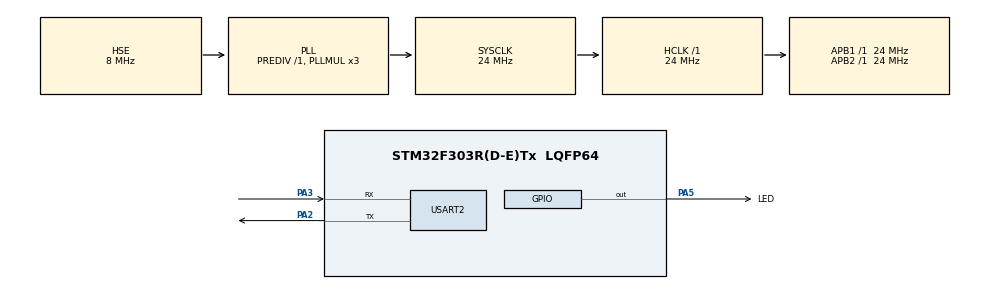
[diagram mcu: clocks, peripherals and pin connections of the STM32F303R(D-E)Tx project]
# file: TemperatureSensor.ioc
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ADC1.Channel-0\#ChannelRegularConversion=ADC_CHANNEL_VREFINT
ADC1.Channel-1\#ChannelRegularConversion=ADC_CHANNEL_TEMPSENSOR
ADC1.ClockPrescaler=ADC_CLOCK_SYNC_PCLK_DIV4
ADC1.DMAContinuousRequests=ENABLE
ADC1.DiscontinuousConvMode=DISABLE
ADC1.EOCSelection=ADC_EOC_SINGLE_CONV
ADC1.ExternalTrigConv=ADC_EXTERNALTRIGCONV_T3_TRGO
ADC1.ExternalTrigConvEdge=ADC_EXTERNALTRIGCONVEDGE_FALLING
ADC1.NbrOfConversion=2
ADC1.NbrOfConversionFlag=1
ADC1.Offset-0\#ChannelRegularConversion=0
ADC1.Offset-1\#ChannelRegularConversion=0
ADC1.OffsetNumber-0\#ChannelRegularConversion=ADC_OFFSET_NONE
ADC1.OffsetNumber-1\#ChannelRegularConversion=ADC_OFFSET_NONE
ADC1.Rank-0\#ChannelRegularConversion=1
ADC1.Rank-1\#ChannelRegularConversion=2
ADC1.SamplingTime-0\#ChannelRegularConversion=ADC_SAMPLETIME_601CYCLES_5
ADC1.SamplingTime-1\#ChannelRegularConversion=ADC_SAMPLETIME_601CYCLES_5
ADC1.SamplingTimeOPAMP-1\#ChannelRegularConversion=ADC_SAMPLETIME_7CYCLES_5
ADC1.master=1
Dma.ADC1.0.Direction=DMA_PERIPH_TO_MEMORY
Dma.ADC1.0.Instance=DMA1_Channel1
Dma.ADC1.0.MemDataAlignment=DMA_MDATAALIGN_HALFWORD
Dma.ADC1.0.MemInc=DMA_MINC_ENABLE
Dma.ADC1.0.Mode=DMA_CIRCULAR
Dma.ADC1.0.PeriphDataAlignment=DMA_PDATAALIGN_HALFWORD
Dma.ADC1.0.PeriphInc=DMA_PINC_DISABLE
Dma.ADC1.0.Priority=DMA_PRIORITY_LOW
Dma.Request0=ADC1
Mcu.Family=STM32F3
Mcu.Name=STM32F303R(D-E)Tx
Mcu.Package=LQFP64
NVIC.ADC1_2_IRQn=true\:0\:0\:false\:false\:true\:true\:true\:true
NVIC.DMA1_Channel1_IRQn=true\:0\:0\:false\:false\:true\:false\:true\:true
NVIC.PriorityGroup=NVIC_PRIORITYGROUP_4
NVIC.TIM3_IRQn=true\:0\:0\:false\:false\:true\:true\:true\:true
PA13.Mode=Serial_Wire
PA13.Signal=SYS_JTMS-SWDIO
PA14.Mode=Serial_Wire
PA14.Signal=SYS_JTCK-SWCLK
PA2.Mode=Asynchronous
PA2.Signal=USART2_TX
PA3.Mode=Asynchronous
PA3.Signal=USART2_RX
PA5.GPIO_Label=LED
PA5.Signal=GPIO_Output
PC14-OSC32_IN.Mode=LSE-External-Oscillator
PC14-OSC32_IN.Signal=RCC_OSC32_IN
PC15-OSC32_OUT.Mode=LSE-External-Oscillator
PC15-OSC32_OUT.Signal=RCC_OSC32_OUT
PF0-OSC_IN.Mode=HSE-External-Clock-Source
PF0-OSC_IN.Signal=RCC_OSC_IN
ProjectManager.HeapSize=0x200
ProjectManager.StackSize=0x400
ProjectManager.TargetToolchain=STM32CubeIDE
RCC.AHBFreq_Value=24000000
RCC.APB1Freq_Value=24000000
RCC.APB1TimFreq_Value=24000000
RCC.APB2Freq_Value=24000000
RCC.APB2TimFreq_Value=24000000
RCC.CortexFreq_Value=24000000
RCC.HCLKFreq_Value=24000000
RCC.HSE_VALUE=8000000
RCC.HSI_VALUE=8000000
RCC.PLLMUL=RCC_PLL_MUL3
RCC.PLLSourceVirtual=RCC_PLLSOURCE_HSE
RCC.SYSCLKFreq_VALUE=24000000
RCC.SYSCLKSourceVirtual=RCC_SYSCLKSOURCE_PLLCLK
RCC.USBFreq_Value=24000000
TIM3.AutoReloadPreload=TIM_AUTORELOAD_PRELOAD_ENABLE
TIM3.Period=17140
TIM3.Prescaler=28
TIM3.TIM_MasterOutputTrigger=TIM_TRGO_UPDATE
USART2.VirtualMode-Asynchronous=VM_ASYNC
VP_ADC1_TempSens_Input.Mode=IN-TempSens
VP_ADC1_Vref_Input.Mode=IN-Vrefint
VP_TIM3_VS_ClockSourceINT.Mode=Internal
board=custom

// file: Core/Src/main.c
/* USER CODE BEGIN Header */
/**
  ******************************************************************************
  * @file           : main.c
  * @brief          : Main program body
  ******************************************************************************
  * @attention
  *
  * Copyright (c) 2024 STMicroelectronics.
  * All rights reserved.
  *
  * This software is licensed under terms that can be found in the LICENSE file
  * in the root directory of this software component.
  * If no LICENSE file comes with this software, it is provided AS-IS.
  *
  ******************************************************************************
  */
/* USER CODE END Header */
#include "main.h"

/* USER CODE BEGIN Includes */
#include <stdio.h>
#include <string.h>
/* USER CODE END Includes */

/* USER CODE BEGIN PD */
#define FULL_SCALE (4095.0F)

#define V_REF_INT_CAL_ADDR ((uint16_t*)	(0x1FFFF7BAU))
#define V_REF_INT_CAL_VREF (3300UL)

#define TS_CAL1_ADDR ((uint16_t*) (0x1FFFF7B8U))
#define TS_CAL1_TEMP ((int32_t) 30)
#define TS_CAL2_ADDR ((uint16_t*) (0x1FFFF7C2U))
#define TS_CAL2_TEMP ((int32_t) 110)
#define TS_CAL_VREF (3300UL)

#define TS_AVG_SLOPE ((float) ((TS_CAL2_TEMP - TS_CAL1_TEMP) / ((float)(*TS_CAL2_ADDR)-(float)(*TS_CAL1_ADDR))))

#define TS_CALC(Vtmeas) ((float) (Vtmeas - (*TS_CAL1_ADDR)) * TS_AVG_SLOPE + TS_CAL1_TEMP)
#define VDDA_CALC(Vmeas) ((float) V_REF_INT_CAL_VREF * (*V_REF_INT_CAL_ADDR) / Vmeas / 1000)
#define VREF_CALC(Vdda, Vref) ((float) Vdda / FULL_SCALE * Vref)
/* USER CODE END PD */

ADC_HandleTypeDef hadc1;
DMA_HandleTypeDef hdma_adc1;

TIM_HandleTypeDef htim3;

UART_HandleTypeDef huart2;

/* USER CODE BEGIN PV */
uint8_t UpdateEvent = 0;
uint16_t AD_RES[2];
float Temperature_meas, Vdda_meas, Vref_meas;
char TxBuffer[60];
/* USER CODE END PV */

void SystemClock_Config(void);
static void MX_GPIO_Init(void);
static void MX_DMA_Init(void);
static void MX_ADC1_Init(void);
static void MX_USART2_UART_Init(void);
static void MX_TIM3_Init(void);

int main(void)
{

  /* MCU Configuration--------------------------------------------------------*/

  /* Reset of all peripherals, Initializes the Flash interface and the Systick. */

	HAL_Init();

  /* Configure the system clock */
  SystemClock_Config();

  /* Initialize all configured peripherals */
  MX_GPIO_Init();
  MX_DMA_Init();
  MX_ADC1_Init();
  MX_USART2_UART_Init();
  MX_TIM3_Init();
  /* USER CODE BEGIN 2 */
  HAL_TIM_Base_Start(&htim3); // Start Timer3 (Trigger Source For ADC1)
  HAL_ADCEx_Calibration_Start(&hadc1, ADC_SINGLE_ENDED);
  HAL_ADC_Start_DMA(&hadc1, (uint32_t*)AD_RES, 2);   // Start ADC Conversion
  sprintf(TxBuffer, "attempt!\r\n Here are calibration data:\r\n");
  HAL_UART_Transmit(&huart2, (uint8_t*)TxBuffer, strlen(TxBuffer), HAL_MAX_DELAY);
  sprintf(TxBuffer, "Vref_calib = %d\r\n", *V_REF_INT_CAL_ADDR);
  HAL_UART_Transmit(&huart2, (uint8_t*)TxBuffer, strlen(TxBuffer), HAL_MAX_DELAY);
  sprintf(TxBuffer, "TS_CAL1 = %d, TS_CAL2 = %d\r\n",*TS_CAL1_ADDR,*TS_CAL2_ADDR);
  HAL_UART_Transmit(&huart2, (uint8_t*)TxBuffer, strlen(TxBuffer), HAL_MAX_DELAY);
  sprintf(TxBuffer, "T_slope = %f\r\n",TS_AVG_SLOPE);
  HAL_UART_Transmit(&huart2, (uint8_t*)TxBuffer, strlen(TxBuffer), HAL_MAX_DELAY);

  /* USER CODE END 2 */

  /* Infinite loop */
  while (1)
  {

    /* USER CODE BEGIN 3 */
      if(UpdateEvent){
          sprintf(TxBuffer, "ADC_CH1_raw = %d , ADC_CH2_raw = %d\r\n", AD_RES[1], AD_RES[0]);
          HAL_UART_Transmit(&huart2, (uint8_t*)TxBuffer, strlen(TxBuffer), HAL_MAX_DELAY);
          Vdda_meas = VDDA_CALC(AD_RES[0]);
          Vref_meas = VREF_CALC(Vdda_meas, AD_RES[0]);
          Temperature_meas = TS_CALC(*V_REF_INT_CAL_ADDR * AD_RES[1] / AD_RES[0]);
          sprintf(TxBuffer, "Vdda = %5.3f [V] , Temp = %4.2f [degC]\r\n", Vdda_meas, Temperature_meas);
          HAL_UART_Transmit(&huart2, (uint8_t*)TxBuffer, strlen(TxBuffer), HAL_MAX_DELAY);
          UpdateEvent = 0;
      }
  }
  /* USER CODE END 3 */
}

void SystemClock_Config(void)
{
  RCC_OscInitTypeDef RCC_OscInitStruct = {0};
  RCC_ClkInitTypeDef RCC_ClkInitStruct = {0};
  RCC_PeriphCLKInitTypeDef PeriphClkInit = {0};

  /** Initializes the RCC Oscillators according to the specified parameters
  * in the RCC_OscInitTypeDef structure.
  */
  RCC_OscInitStruct.OscillatorType = RCC_OSCILLATORTYPE_HSE;
  RCC_OscInitStruct.HSEState = RCC_HSE_BYPASS;
  RCC_OscInitStruct.HSIState = RCC_HSI_ON;
  RCC_OscInitStruct.PLL.PLLState = RCC_PLL_ON;
  RCC_OscInitStruct.PLL.PLLSource = RCC_PLLSOURCE_HSE;
  RCC_OscInitStruct.PLL.PLLMUL = RCC_PLL_MUL3;
  RCC_OscInitStruct.PLL.PREDIV = RCC_PREDIV_DIV1;
  if (HAL_RCC_OscConfig(&RCC_OscInitStruct) != HAL_OK)
  {
    Error_Handler();
  }

  /** Initializes the CPU, AHB and APB buses clocks
  */
  RCC_ClkInitStruct.ClockType = RCC_CLOCKTYPE_HCLK|RCC_CLOCKTYPE_SYSCLK
                              |RCC_CLOCKTYPE_PCLK1|RCC_CLOCKTYPE_PCLK2;
  RCC_ClkInitStruct.SYSCLKSource = RCC_SYSCLKSOURCE_PLLCLK;
  RCC_ClkInitStruct.AHBCLKDivider = RCC_SYSCLK_DIV1;
  RCC_ClkInitStruct.APB1CLKDivider = RCC_HCLK_DIV1;
  RCC_ClkInitStruct.APB2CLKDivider = RCC_HCLK_DIV1;

  if (HAL_RCC_ClockConfig(&RCC_ClkInitStruct, FLASH_LATENCY_0) != HAL_OK)
  {
    Error_Handler();
  }
  PeriphClkInit.PeriphClockSelection = RCC_PERIPHCLK_USART2|RCC_PERIPHCLK_TIM34;
  PeriphClkInit.Usart2ClockSelection = RCC_USART2CLKSOURCE_PCLK1;
  PeriphClkInit.Tim34ClockSelection = RCC_TIM34CLK_HCLK;
  if (HAL_RCCEx_PeriphCLKConfig(&PeriphClkInit) != HAL_OK)
  {
    Error_Handler();
  }
}

static void MX_ADC1_Init(void)
{

  ADC_MultiModeTypeDef multimode = {0};
  ADC_ChannelConfTypeDef sConfig = {0};

  /** Common config
  */
  hadc1.Instance = ADC1;
  hadc1.Init.ClockPrescaler = ADC_CLOCK_SYNC_PCLK_DIV4;
  hadc1.Init.Resolution = ADC_RESOLUTION_12B;
  hadc1.Init.ScanConvMode = ADC_SCAN_ENABLE;
  hadc1.Init.ContinuousConvMode = DISABLE;
  hadc1.Init.DiscontinuousConvMode = DISABLE;
  hadc1.Init.ExternalTrigConvEdge = ADC_EXTERNALTRIGCONVEDGE_FALLING;
  hadc1.Init.ExternalTrigConv = ADC_EXTERNALTRIGCONV_T3_TRGO;
  hadc1.Init.DataAlign = ADC_DATAALIGN_RIGHT;
  hadc1.Init.NbrOfConversion = 2;
  hadc1.Init.DMAContinuousRequests = ENABLE;
  hadc1.Init.EOCSelection = ADC_EOC_SINGLE_CONV;
  hadc1.Init.LowPowerAutoWait = DISABLE;
  hadc1.Init.Overrun = ADC_OVR_DATA_OVERWRITTEN;
  if (HAL_ADC_Init(&hadc1) != HAL_OK)
  {
    Error_Handler();
  }

  /** Configure the ADC multi-mode
  */
  multimode.Mode = ADC_MODE_INDEPENDENT;
  if (HAL_ADCEx_MultiModeConfigChannel(&hadc1, &multimode) != HAL_OK)
  {
    Error_Handler();
  }

  /** Configure Regular Channel
  */
  sConfig.Channel = ADC_CHANNEL_VREFINT;
  sConfig.Rank = ADC_REGULAR_RANK_1;
  sConfig.SingleDiff = ADC_SINGLE_ENDED;
  sConfig.SamplingTime = ADC_SAMPLETIME_601CYCLES_5;
  sConfig.OffsetNumber = ADC_OFFSET_NONE;
  sConfig.Offset = 0;
  if (HAL_ADC_ConfigChannel(&hadc1, &sConfig) != HAL_OK)
  {
    Error_Handler();
  }

  /** Configure Regular Channel
  */
  sConfig.Channel = ADC_CHANNEL_TEMPSENSOR;
  sConfig.Rank = ADC_REGULAR_RANK_2;
  if (HAL_ADC_ConfigChannel(&hadc1, &sConfig) != HAL_OK)
  {
    Error_Handler();
  }

}

static void MX_TIM3_Init(void)
{

  TIM_ClockConfigTypeDef sClockSourceConfig = {0};
  TIM_MasterConfigTypeDef sMasterConfig = {0};

  htim3.Instance = TIM3;
  htim3.Init.Prescaler = 28;
  htim3.Init.CounterMode = TIM_COUNTERMODE_UP;
  htim3.Init.Period = 17140;
  htim3.Init.ClockDivision = TIM_CLOCKDIVISION_DIV1;
  htim3.Init.AutoReloadPreload = TIM_AUTORELOAD_PRELOAD_ENABLE;
  if (HAL_TIM_Base_Init(&htim3) != HAL_OK)
  {
    Error_Handler();
  }
  sClockSourceConfig.ClockSource = TIM_CLOCKSOURCE_INTERNAL;
  if (HAL_TIM_ConfigClockSource(&htim3, &sClockSourceConfig) != HAL_OK)
  {
    Error_Handler();
  }
  sMasterConfig.MasterOutputTrigger = TIM_TRGO_UPDATE;
  sMasterConfig.MasterSlaveMode = TIM_MASTERSLAVEMODE_DISABLE;
  if (HAL_TIMEx_MasterConfigSynchronization(&htim3, &sMasterConfig) != HAL_OK)
  {
    Error_Handler();
  }

}

static void MX_USART2_UART_Init(void)
{

  huart2.Instance = USART2;
  huart2.Init.BaudRate = 38400;
  huart2.Init.WordLength = UART_WORDLENGTH_8B;
  huart2.Init.StopBits = UART_STOPBITS_1;
  huart2.Init.Parity = UART_PARITY_NONE;
  huart2.Init.Mode = UART_MODE_TX_RX;
  huart2.Init.HwFlowCtl = UART_HWCONTROL_NONE;
  huart2.Init.OverSampling = UART_OVERSAMPLING_16;
  huart2.Init.OneBitSampling = UART_ONE_BIT_SAMPLE_DISABLE;
  huart2.AdvancedInit.AdvFeatureInit = UART_ADVFEATURE_NO_INIT;
  if (HAL_UART_Init(&huart2) != HAL_OK)
  {
    Error_Handler();
  }

}

static void MX_DMA_Init(void)
{

  /* DMA controller clock enable */
  __HAL_RCC_DMA1_CLK_ENABLE();

  /* DMA interrupt init */
  /* DMA1_Channel1_IRQn interrupt configuration */
  HAL_NVIC_SetPriority(DMA1_Channel1_IRQn, 0, 0);
  HAL_NVIC_EnableIRQ(DMA1_Channel1_IRQn);

}

static void MX_GPIO_Init(void)
{
  GPIO_InitTypeDef GPIO_InitStruct = {0};

  /* GPIO Ports Clock Enable */
  __HAL_RCC_GPIOC_CLK_ENABLE();
  __HAL_RCC_GPIOF_CLK_ENABLE();
  __HAL_RCC_GPIOA_CLK_ENABLE();

  /*Configure GPIO pin Output Level */
  HAL_GPIO_WritePin(LED_GPIO_Port, LED_Pin, GPIO_PIN_RESET);

  /*Configure GPIO pin : LED_Pin */
  GPIO_InitStruct.Pin = LED_Pin;
  GPIO_InitStruct.Mode = GPIO_MODE_OUTPUT_PP;
  GPIO_InitStruct.Pull = GPIO_NOPULL;
  GPIO_InitStruct.Speed = GPIO_SPEED_FREQ_LOW;
  HAL_GPIO_Init(LED_GPIO_Port, &GPIO_InitStruct);

}

/* USER CODE BEGIN 4 */
void HAL_ADC_ConvCpltCallback(ADC_HandleTypeDef* hadc)
{
    HAL_GPIO_TogglePin(LED_GPIO_Port, LED_Pin); // Toggle Interrupt Rate Indicator Pin
    UpdateEvent = 1;
}
/* USER CODE END 4 */

void Error_Handler(void)
{
  __disable_irq();
  while (1)
  {
  }
}
